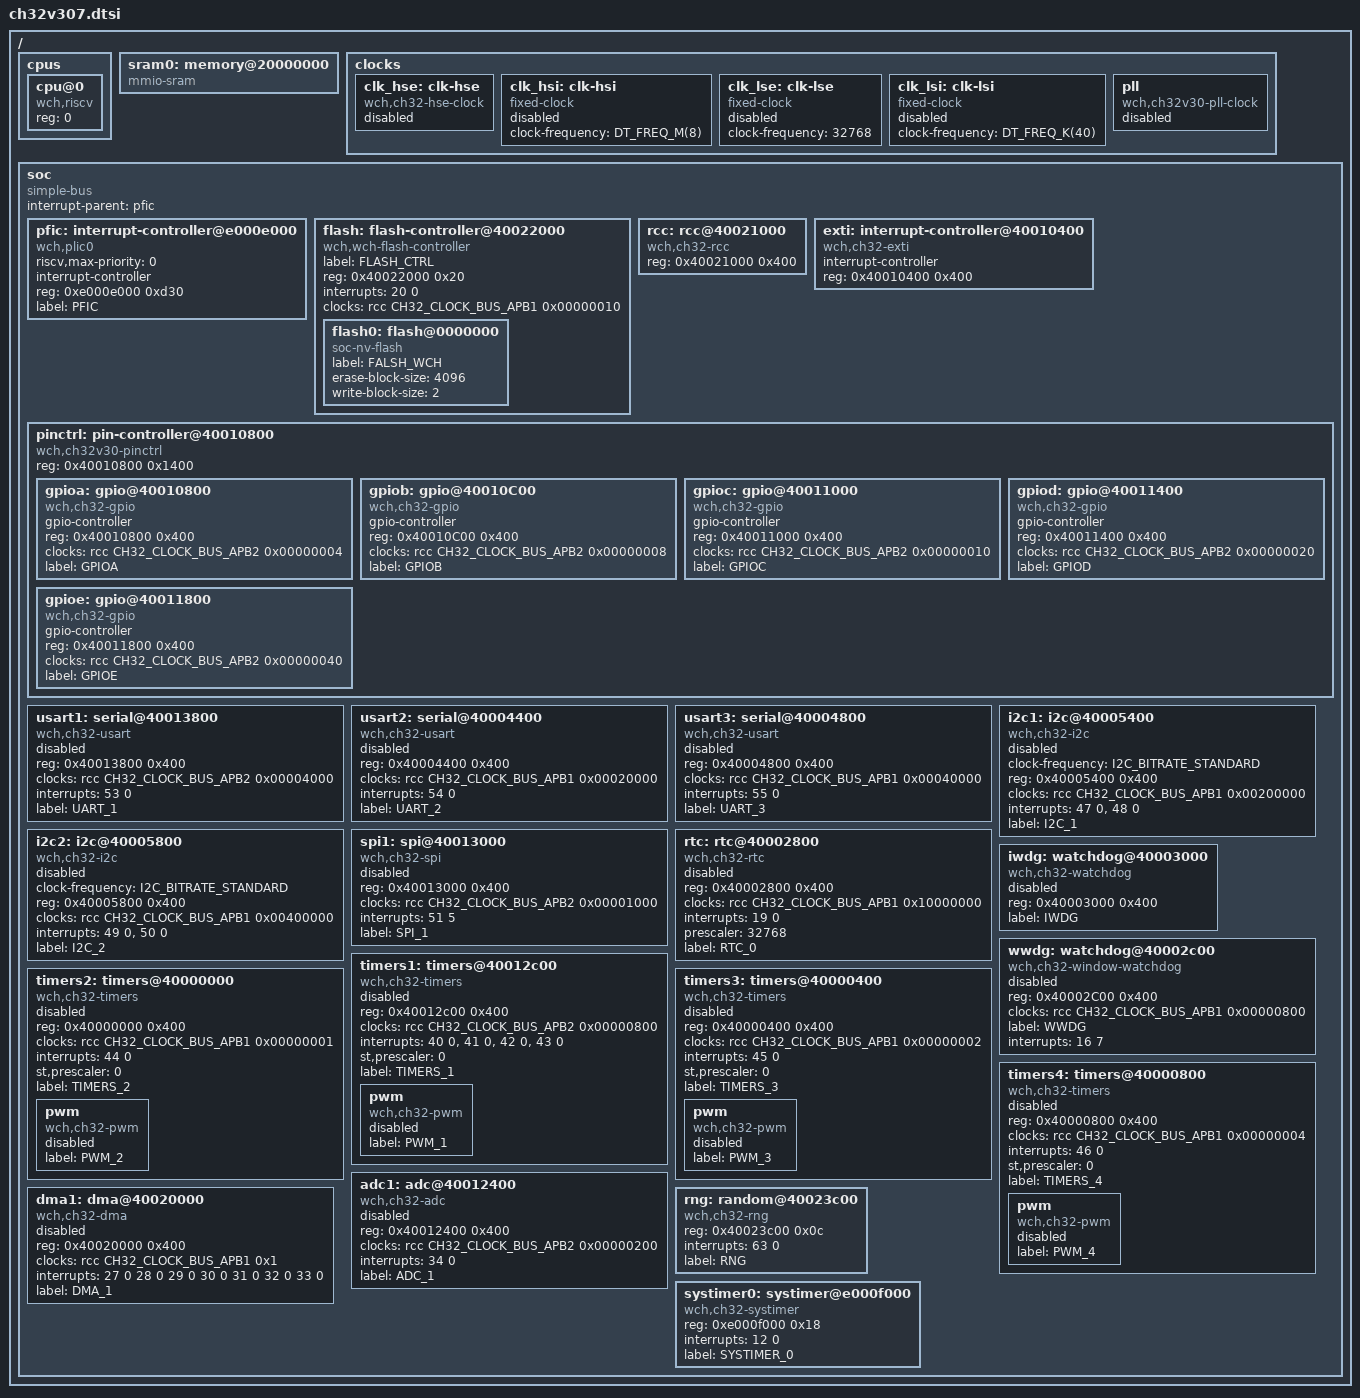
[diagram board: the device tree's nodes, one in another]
/*
* Copyright (c) 2021 Nanjing Qinheng Microelectronics Co., Ltd.
*
* SPDX-License-Identifier: Apache-2.0
*/

#include <dt-bindings/clock/ch32_clock.h>
#include <dt-bindings/i2c/i2c.h>
#include <dt-bindings/gpio/gpio.h>
#include <dt-bindings/pwm/pwm.h>
#include <freq.h>

/ {
	#address-cells = <1>;
	#size-cells = <1>;

	cpus {
		#address-cells = <1>;
		#size-cells = <0>;
 
		cpu@0 {
			device_type = "cpu";
			compatible = "wch,riscv";
			reg = <0>;
		};
	};
 
	sram0: memory@20000000 {
		compatible = "mmio-sram";
	};

	clocks {
		clk_hse: clk-hse {
			#clock-cells = <0>;
			compatible = "wch,ch32-hse-clock";
			status = "disabled";
		};

		clk_hsi: clk-hsi {
			#clock-cells = <0>;
			compatible = "fixed-clock";
			clock-frequency = <DT_FREQ_M(8)>;
			status = "disabled";
		};

		clk_lse: clk-lse {
			#clock-cells = <0>;
			compatible = "fixed-clock";
			clock-frequency = <32768>;
			status = "disabled";
		};

		clk_lsi: clk-lsi {
			#clock-cells = <0>;
			compatible = "fixed-clock";
			clock-frequency = <DT_FREQ_K(40)>;
			status = "disabled";
		};

		pll: pll {
			#clock-cells = <0>;
			compatible = "wch,ch32v30-pll-clock";
			status = "disabled";
		};
	};

	soc {
		#address-cells = <1>;
		#size-cells = <1>;
		compatible ="simple-bus";
		interrupt-parent = <&pfic>;
		ranges;
	
		pfic: interrupt-controller@e000e000 {
			#interrupt-cells = <2>;
			compatible = "wch,plic0";
			riscv,max-priority = <0>;
			interrupt-controller;
			reg = <0xe000e000 0xd30>;
			label = "PFIC";
			status = "okay";
		};

		flash: flash-controller@40022000 {
			compatible = "wch,wch-flash-controller";
			label = "FLASH_CTRL";
			reg = <0x40022000 0x20>;
			interrupts = <20 0>;
			clocks = <&rcc CH32_CLOCK_BUS_APB1 0x00000010>;

			#address-cells = <1>;
			#size-cells = <1>;

			flash0: flash@0000000 {
				compatible = "soc-nv-flash";
				label = "FALSH_WCH";

				erase-block-size = <4096>;
				write-block-size = <2>;
			};
		};
	
		rcc: rcc@40021000 {
			compatible = "wch,ch32-rcc";
			#clock-cells = <2>;
			reg = <0x40021000 0x400>;
		};

		exti: interrupt-controller@40010400 {
			compatible = "wch,ch32-exti";
			interrupt-controller;
			#interrupt-cells = <1>;
			reg = <0x40010400 0x400>;
		};

		pinctrl: pin-controller@40010800 {
			compatible = "wch,ch32v30-pinctrl";
			#address-cells = <1>;
			#size-cells = <1>;
			reg = <0x40010800 0x1400>;

			gpioa: gpio@40010800 {
				compatible = "wch,ch32-gpio";
				gpio-controller;
				#gpio-cells = <2>;
				reg = <0x40010800 0x400>;
				clocks = <&rcc CH32_CLOCK_BUS_APB2 0x00000004>;
				label = "GPIOA";
			};

			gpiob: gpio@40010C00 {
				compatible = "wch,ch32-gpio";
				gpio-controller;
				#gpio-cells = <2>;
				reg = <0x40010C00 0x400>;
				clocks = <&rcc CH32_CLOCK_BUS_APB2 0x00000008>;
				label = "GPIOB";
			};

			gpioc: gpio@40011000 {
				compatible = "wch,ch32-gpio";
				gpio-controller;
				#gpio-cells = <2>;
				reg = <0x40011000 0x400>;
				clocks = <&rcc CH32_CLOCK_BUS_APB2 0x00000010>;
				label = "GPIOC";
			};

			gpiod: gpio@40011400 {
				compatible = "wch,ch32-gpio";
				gpio-controller;
				#gpio-cells = <2>;
				reg = <0x40011400 0x400>;
				clocks = <&rcc CH32_CLOCK_BUS_APB2 0x00000020>;
				label = "GPIOD";
			};

			gpioe: gpio@40011800 {
				compatible = "wch,ch32-gpio";
				gpio-controller;
				#gpio-cells = <2>;
				reg = <0x40011800 0x400>;
				clocks = <&rcc CH32_CLOCK_BUS_APB2 0x00000040>;
				label = "GPIOE";
			};
		};

		usart1: serial@40013800 {
			compatible = "wch,ch32-usart", "wch,ch32-uart";
			reg = <0x40013800 0x400>;
			clocks = <&rcc CH32_CLOCK_BUS_APB2 0x00004000>;
			interrupts = <53 0>;
			status = "disabled";
			label = "UART_1";
		};

		usart2: serial@40004400 {
			compatible = "wch,ch32-usart", "wch,ch32-uart";
			reg = <0x40004400 0x400>;
			clocks = <&rcc CH32_CLOCK_BUS_APB1 0x00020000>;
			interrupts = <54 0>;
			status = "disabled";
			label = "UART_2";
		};

		usart3: serial@40004800 {
			compatible = "wch,ch32-usart", "wch,ch32-uart";
			reg = <0x40004800 0x400>;
			clocks = <&rcc CH32_CLOCK_BUS_APB1 0x00040000>;
			interrupts = <55 0>;
			status = "disabled";
			label = "UART_3";
		};

		i2c1: i2c@40005400 {
			compatible = "wch,ch32-i2c";
			clock-frequency = <I2C_BITRATE_STANDARD>;
			#address-cells = <1>;
			#size-cells = <0>;
			reg = <0x40005400 0x400>;
			clocks = <&rcc CH32_CLOCK_BUS_APB1 0x00200000>;
			interrupts = <47 0>, <48 0>;
			interrupt-names = "event", "error";
			status = "disabled";
			label= "I2C_1";
		};

		i2c2: i2c@40005800 {
			compatible = "wch,ch32-i2c";
			clock-frequency = <I2C_BITRATE_STANDARD>;
			#address-cells = <1>;
			#size-cells = <0>;
			reg = <0x40005800 0x400>;
			clocks = <&rcc CH32_CLOCK_BUS_APB1 0x00400000>;
			interrupts = <49 0>, <50 0>;
			interrupt-names ="event", "error";
			status = "disabled";
			label= "I2C_2";
		};

		spi1: spi@40013000 {
			compatible = "wch,ch32-spi";
			#address-cells = <1>;
			#size-cells = <0>;
			reg = <0x40013000 0x400>;
			clocks = <&rcc CH32_CLOCK_BUS_APB2 0x00001000>;
			interrupts = <51 5>;
			status = "disabled";
			label = "SPI_1";
		};

		rtc: rtc@40002800 {
			compatible = "wch,ch32-rtc";
			reg = <0x40002800 0x400>;
			clocks = <&rcc CH32_CLOCK_BUS_APB1 0x10000000>;
			interrupts = <19 0>;
			prescaler = <32768>;
			status = "disabled";
			label = "RTC_0";
		};

		iwdg: watchdog@40003000 {
			compatible = "wch,ch32-watchdog";
			reg = <0x40003000 0x400>;
			label = "IWDG";
			status = "disabled";
		};

		wwdg: watchdog@40002c00 {
			compatible = "wch,ch32-window-watchdog";
			reg = <0x40002C00 0x400>;
			clocks = <&rcc CH32_CLOCK_BUS_APB1 0x00000800>;
			label = "WWDG";
			interrupts = <16 7>;
			status = "disabled";
		};

		timers1: timers@40012c00 {
			compatible = "wch,ch32-timers";
			reg = <0x40012c00 0x400>;
			clocks = <&rcc CH32_CLOCK_BUS_APB2 0x00000800>;
			interrupts = <40 0>, <41 0>, <42 0>, <43 0>;
			interrupt-names = "brk", "up", "trgcom", "cc";
			st,prescaler = <0>;
			status = "disabled";
			label = "TIMERS_1";

			pwm {
				compatible = "wch,ch32-pwm";
				status = "disabled";
				label = "PWM_1";
				#pwm-cells = <3>;
			};
		};

		timers2: timers@40000000 {
			compatible = "wch,ch32-timers";
			reg = <0x40000000 0x400>;
			clocks = <&rcc CH32_CLOCK_BUS_APB1 0x00000001>;
			interrupts = <44 0>;
			interrupt-names = "global";
			st,prescaler = <0>;
			status = "disabled";
			label = "TIMERS_2";

			pwm {
				compatible = "wch,ch32-pwm";
				status = "disabled";
				label = "PWM_2";
				#pwm-cells = <3>;
			};
		};

		timers3: timers@40000400 {
			compatible = "wch,ch32-timers";
			reg = <0x40000400 0x400>;
			clocks = <&rcc CH32_CLOCK_BUS_APB1 0x00000002>;
			interrupts = <45 0>;
			interrupt-names = "global";
			st,prescaler = <0>;
			status = "disabled";
			label = "TIMERS_3";

			pwm {
				compatible = "wch,ch32-pwm";
				status = "disabled";
				label = "PWM_3";
				#pwm-cells = <3>;
			};
		};

		timers4: timers@40000800 {
			compatible = "wch,ch32-timers";
			reg = <0x40000800 0x400>;
			clocks = <&rcc CH32_CLOCK_BUS_APB1 0x00000004>;
			interrupts = <46 0>;
			interrupt-names = "global";
			st,prescaler = <0>;
			status = "disabled";
			label = "TIMERS_4";

			pwm {
				compatible = "wch,ch32-pwm";
				status = "disabled";
				label = "PWM_4";
				#pwm-cells = <3>;
			};
		};

		adc1: adc@40012400 {
			compatible = "wch,ch32-adc";
			reg = <0x40012400 0x400>;
			clocks = <&rcc CH32_CLOCK_BUS_APB2 0x00000200>;
			interrupts = <34 0>;
			status = "disabled";
			label = "ADC_1";
			#io-channel-cells = <1>;
		};

		dma1: dma@40020000 {
			compatible = "wch,ch32-dma";
			#dma-cells = <2>;
			reg = <0x40020000 0x400>;
			clocks = <&rcc CH32_CLOCK_BUS_APB1 0x1>;
			interrupts = <27 0 28 0 29 0 30 0 31 0 32 0 33 0>;
			status = "disabled";
			label = "DMA_1";
		};

		rng: random@40023c00{
			compatible = "wch,ch32-rng";
			reg = <0x40023c00 0x0c>;
			interrupts = <63 0>;
			status = "okay";
			label = "RNG";
		};

		systimer0: systimer@e000f000{
			compatible = "wch,ch32-systimer";
			reg = <0xe000f000 0x18>;
			interrupts = <12 0>;
			status = "okay";
			label = "SYSTIMER_0";
		};
	};
};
